AUTOSAR XML (schema 314)
package /ComponentType
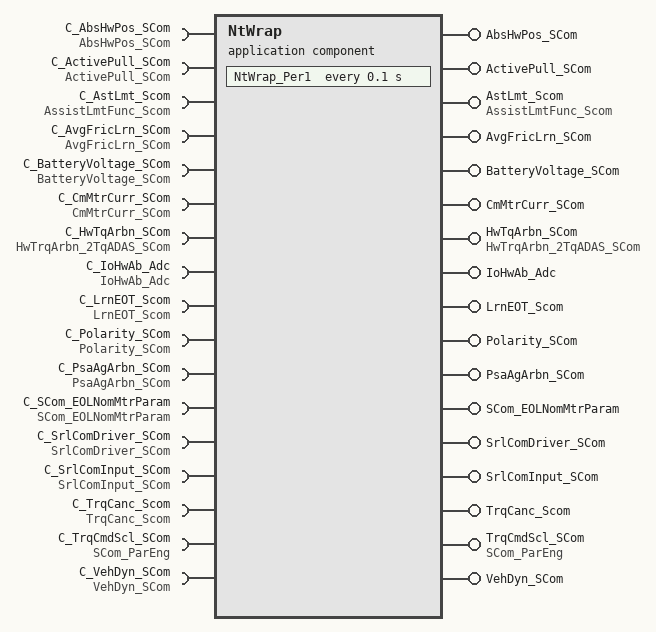
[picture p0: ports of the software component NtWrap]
  application software component type NtWrap
    17 x provide port:
      AbsHwPos_SCom: provided-interface=AbsHwPos_SCom
        provided-com-specs:
          operation=CustClrTrim, queue-length=1
          operation=CustSetTrim, queue-length=1
          operation=NxtClearTrim, queue-length=1
          operation=NxtSetTrim, queue-length=1
      ActivePull_SCom: provided-interface=ActivePull_SCom
        provided-com-specs:
          operation=ReadParam, queue-length=1
          operation=Reset, queue-length=1
          operation=SetLTComp, queue-length=1
          operation=SetSTComp, queue-length=1
      AstLmt_Scom: server-com-spec{operation=ManualTrqCmd, queue-length=1}, provided-interface=AssistLmtFunc_Scom
      AvgFricLrn_SCom: provided-interface=AvgFricLrn_SCom
        provided-com-specs:
          operation=CaptureOnTheFly, queue-length=1
          operation=GetEOLFric, queue-length=1
          operation=GetOffsetOutputDefeat, queue-length=1
          operation=GetSelect, queue-length=1
          operation=InitLearnedTables, queue-length=1
          operation=ResetToZero, queue-length=1
          operation=SetEOLFric, queue-length=1
          operation=SetOffsetOutputDefeat, queue-length=1
          operation=SetSelect, queue-length=1
      BatteryVoltage_SCom: provided-com-specs=[{operation=ClearTransOvData, queue-length=1}, {operation=ReadTransOvData, queue-length=1}], provided-interface=BatteryVoltage_SCom
      CmMtrCurr_SCom: provided-interface=CmMtrCurr_SCom
        provided-com-specs:
          operation=CalGain, queue-length=1
          operation=CalOffset, queue-length=1
          operation=MtrCurrOffReadStatus, queue-length=1
          operation=ReadMtrCurrCals, queue-length=1
          operation=SetMtrCurrCals, queue-length=1
      HwTqArbn_SCom: provided-interface=HwTrqArbn_2TqADAS_SCom
        provided-com-specs:
          operation=ClrHwTrqArbOffsetTrim, queue-length=1
          operation=ReadHwTrqArbOffsetTrim, queue-length=1
          operation=SetHwTrqArbOffsetTrim, queue-length=1
          operation=WriteHwTrqArbOffsetTrim, queue-length=1
      IoHwAb_Adc: server-com-spec{operation=ResetAdcEnable, queue-length=1}, provided-interface=IoHwAb_Adc
      LrnEOT_Scom: server-com-spec{operation=ResetEOT, queue-length=1}, provided-interface=LrnEOT_Scom
      Polarity_SCom: provided-com-specs=[{operation=ReadPolarity, queue-length=1}, {operation=SetPolarity, queue-length=1}], provided-interface=Polarity_SCom
      PsaAgArbn_SCom: server-com-spec{operation=PsaAaCmd, queue-length=1}, provided-interface=PsaAgArbn_SCom
      SCom_EOLNomMtrParam: provided-com-specs=[{operation=Get, queue-length=1}, {operation=Set, queue-length=1}], provided-interface=SCom_EOLNomMtrParam
      SrlComDriver_SCom: provided-interface=SrlComDriver_SCom
        provided-com-specs:
          operation=ElecIntStart, queue-length=1
          operation=ElecIntStop, queue-length=1
          operation=GetBusOffCounter, queue-length=1
          operation=SendMsgOnChange, queue-length=1
      SrlComInput_SCom: provided-interface=SrlComInput_SCom
        provided-com-specs:
          operation=GetNetworkDiagFltAcc, queue-length=1
          operation=ManualVehSpd, queue-length=1
          operation=ResetTimers, queue-length=1
          operation=VehSpdControl, queue-length=1
      TrqCanc_Scom: provided-interface=TrqCanc_Scom
        provided-com-specs:
          operation=ReadCogTrqCal, queue-length=1
          operation=ReadCogTrqCalComp, queue-length=1
          operation=SetCogTrqCal, queue-length=1
          operation=SetCogTrqCalComp, queue-length=1
      TrqCmdScl_SCom: provided-com-specs=[{operation=Get, queue-length=1}, {operation=Set, queue-length=1}], provided-interface=SCom_ParEng
      VehDyn_SCom: provided-com-specs=[{operation=ForceCenter, queue-length=1}, {operation=ResetCenter, queue-length=1}], provided-interface=VehDyn_SCom
    17 x require port:
      C_AbsHwPos_SCom: required-com-specs=[CustClrTrim, CustSetTrim, NxtClearTrim, NxtSetTrim], required-interface=AbsHwPos_SCom
      C_ActivePull_SCom: required-com-specs=[ReadParam, Reset, SetLTComp, SetSTComp], required-interface=ActivePull_SCom
      C_AstLmt_Scom: client-com-spec=ManualTrqCmd, required-interface=AssistLmtFunc_Scom
      C_AvgFricLrn_SCom: required-interface=AvgFricLrn_SCom
        required-com-specs:
          CaptureOnTheFly
          GetEOLFric
          GetOffsetOutputDefeat
          GetSelect
          InitLearnedTables
          ResetToZero
          SetEOLFric
          SetOffsetOutputDefeat
          SetSelect
      C_BatteryVoltage_SCom: required-com-specs=[ClearTransOvData, ReadTransOvData], required-interface=BatteryVoltage_SCom
      C_CmMtrCurr_SCom: required-com-specs=[CalGain, CalOffset, MtrCurrOffReadStatus, ReadMtrCurrCals, SetMtrCurrCals], required-interface=CmMtrCurr_SCom
      C_HwTqArbn_SCom: required-com-specs=[ClrHwTrqArbOffsetTrim, ReadHwTrqArbOffsetTrim, SetHwTrqArbOffsetTrim, WriteHwTrqArbOffsetTrim], required-interface=HwTrqArbn_2TqADAS_SCom
      C_IoHwAb_Adc: client-com-spec=ResetAdcEnable, required-interface=IoHwAb_Adc
      C_LrnEOT_Scom: client-com-spec=ResetEOT, required-interface=LrnEOT_Scom
      C_Polarity_SCom: required-com-specs=[ReadPolarity, SetPolarity], required-interface=Polarity_SCom
      C_PsaAgArbn_SCom: client-com-spec=PsaAaCmd, required-interface=PsaAgArbn_SCom
      C_SCom_EOLNomMtrParam: required-com-specs=[Get, Set], required-interface=SCom_EOLNomMtrParam
      C_SrlComDriver_SCom: required-com-specs=[ElecIntStart, ElecIntStop, GetBusOffCounter, SendMsgOnChange], required-interface=SrlComDriver_SCom
      C_SrlComInput_SCom: required-com-specs=[GetNetworkDiagFltAcc, ManualVehSpd, ResetTimers, VehSpdControl], required-interface=SrlComInput_SCom
      C_TrqCanc_Scom: required-com-specs=[ReadCogTrqCal, ReadCogTrqCalComp, SetCogTrqCal, SetCogTrqCalComp], required-interface=TrqCanc_Scom
      C_TrqCmdScl_SCom: required-com-specs=[Get, Set], required-interface=SCom_ParEng
      C_VehDyn_SCom: required-com-specs=[ForceCenter, ResetCenter], required-interface=VehDyn_SCom
  internal behavior NtWrap_InternalBehavior: component=NtWrap
    timing event TMT_NtWrap_Per1: start-on-event=NtWrap_Per1, period=0.1
    33 x operation invoked event:
      OIT_NtWrapC_AbsHwPos_SCom_CustClrTrim_AbsHwPos_SCom_CustClrTrim: start-on-event=NtWrapC_AbsHwPos_SCom_CustClrTrim, operation=AbsHwPos_SCom.CustClrTrim
      OIT_NtWrapC_AbsHwPos_SCom_CustSetTrim_AbsHwPos_SCom_CustSetTrim: start-on-event=NtWrapC_AbsHwPos_SCom_CustSetTrim, operation=AbsHwPos_SCom.CustSetTrim
      OIT_NtWrapC_AbsHwPos_SCom_NxtClearTrim_AbsHwPos_SCom_NxtClearTrim: start-on-event=NtWrapC_AbsHwPos_SCom_NxtClearTrim, operation=AbsHwPos_SCom.NxtClearTrim
      OIT_NtWrapC_AbsHwPos_SCom_NxtSetTrim_AbsHwPos_SCom_NxtSetTrim: start-on-event=NtWrapC_AbsHwPos_SCom_NxtSetTrim, operation=AbsHwPos_SCom.NxtSetTrim
      OIT_NtWrapC_ActivePull_SCom_SetLTComp_ActivePull_SCom_SetLTComp: start-on-event=NtWrapC_ActivePull_SCom_SetLTComp, operation=ActivePull_SCom.SetLTComp
      OIT_NtWrapC_ActivePull_SCom_SetSTComp_ActivePull_SCom_SetSTComp: start-on-event=NtWrapC_ActivePull_SCom_SetSTComp, operation=ActivePull_SCom.SetSTComp
      OIT_NtWrapC_AstLmt_Scom_ManualTrqCmd_AstLmt_Scom_ManualTrqCmd: start-on-event=NtWrapC_AstLmt_Scom_ManualTrqCmd, operation=AstLmt_Scom.ManualTrqCmd
      OIT_NtWrapC_AvgFricLrn_SCom_InitLearnedTables_AvgFricLrn_SCom_InitLearnedTables: start-on-event=NtWrapC_AvgFricLrn_SCom_InitLearnedTables, operation=AvgFricLrn_SCom.InitLearnedTables
      OIT_NtWrapC_AvgFricLrn_SCom_ResetToZero_AvgFricLrn_SCom_ResetToZero: start-on-event=NtWrapC_AvgFricLrn_SCom_ResetToZero, operation=AvgFricLrn_SCom.ResetToZero
      OIT_NtWrapC_AvgFricLrn_SCom_SetEOLFric_AvgFricLrn_SCom_SetEOLFric: start-on-event=NtWrapC_AvgFricLrn_SCom_SetEOLFric, operation=AvgFricLrn_SCom.SetEOLFric
      OIT_NtWrapC_AvgFricLrn_SCom_SetOffsetOutputDefeat_AvgFricLrn_SCom_SetOffsetOutputDefeat: start-on-event=NtWrapC_AvgFricLrn_SCom_SetOffsetOutputDefeat, operation=AvgFricLrn_SCom.SetOffsetOutputDefeat
      OIT_NtWrapC_AvgFricLrn_SCom_SetSelect_AvgFricLrn_SCom_SetSelect: start-on-event=NtWrapC_AvgFricLrn_SCom_SetSelect, operation=AvgFricLrn_SCom.SetSelect
      OIT_NtWrapC_BatteryVoltage_SCom_ClearTransOvData_BatteryVoltage_SCom_ClearTransOvData: start-on-event=NtWrapC_BatteryVoltage_SCom_ClearTransOvData, operation=BatteryVoltage_SCom.ClearTransOvData
      OIT_NtWrapC_CmMtrCurr_SCom_CalGain_CmMtrCurr_SCom_CalGain: start-on-event=NtWrapC_CmMtrCurr_SCom_CalGain, operation=CmMtrCurr_SCom.CalGain
      OIT_NtWrapC_CmMtrCurr_SCom_CalOffset_CmMtrCurr_SCom_CalOffset: start-on-event=NtWrapC_CmMtrCurr_SCom_CalOffset, operation=CmMtrCurr_SCom.CalOffset
      OIT_NtWrapC_CmMtrCurr_SCom_SetMtrCurrCals_CmMtrCurr_SCom_SetMtrCurrCals: start-on-event=NtWrapC_CmMtrCurr_SCom_SetMtrCurrCals, operation=CmMtrCurr_SCom.SetMtrCurrCals
      OIT_NtWrapC_HwTqArbn_SCom_ClrTrqTrim_HwTqArbn_SCom_ClrHwTrqArbOffsetTrim: start-on-event=NtWrapC_HwTqArbn_SCom_ClrTrqTrim, operation=HwTqArbn_SCom.ClrHwTrqArbOffsetTrim
      OIT_NtWrapC_HwTqArbn_SCom_SetTrqTrim_HwTqArbn_SCom_SetHwTrqArbOffsetTrim: start-on-event=NtWrapC_HwTqArbn_SCom_SetTrqTrim, operation=HwTqArbn_SCom.SetHwTrqArbOffsetTrim
      OIT_NtWrapC_HwTqArbn_SCom_WriteData_HwTqArbn_SCom_WriteHwTrqArbOffsetTrim: start-on-event=NtWrapC_HwTqArbn_SCom_WriteData, operation=HwTqArbn_SCom.WriteHwTrqArbOffsetTrim
      OIT_NtWrapC_IoHwAb_Adc_ResetAdcEnable_IoHwAb_Adc_ResetAdcEnable: start-on-event=NtWrapC_IoHwAb_Adc_ResetAdcEnable, operation=IoHwAb_Adc.ResetAdcEnable
      OIT_NtWrapC_LrnEOT_Scom_ResetEOT_LrnEOT_Scom_ResetEOT: start-on-event=NtWrapC_LrnEOT_Scom_ResetEOT, operation=LrnEOT_Scom.ResetEOT
      OIT_NtWrapC_Polarity_SCom_SetPolarity_Polarity_SCom_SetPolarity: start-on-event=NtWrapC_Polarity_SCom_SetPolarity, operation=Polarity_SCom.SetPolarity
      OIT_NtWrapC_PsaAgArbn_SCom_PsaAaCmd_PsaAgArbn_SCom_PsaAaCmd: start-on-event=NtWrapC_PsaAgArbn_SCom_PsaAaCmd, operation=PsaAgArbn_SCom.PsaAaCmd
      OIT_NtWrapC_SCom_EOLNomMtrParam_Set_SCom_EOLNomMtrParam_Set: start-on-event=NtWrapC_SCom_EOLNomMtrParam_Set, operation=SCom_EOLNomMtrParam.Set
      OIT_NtWrapC_SrlComDriver_SCom_ElecIntStart_SrlComDriver_SCom_ElecIntStart: start-on-event=NtWrapC_SrlComDriver_SCom_ElecIntStart, operation=SrlComDriver_SCom.ElecIntStart
      OIT_NtWrapC_SrlComDriver_SCom_ElecIntStop_SrlComDriver_SCom_ElecIntStop: start-on-event=NtWrapC_SrlComDriver_SCom_ElecIntStop, operation=SrlComDriver_SCom.ElecIntStop
      OIT_NtWrapC_SrlComDriver_SCom_SendMsgOnChange_SrlComDriver_SCom_SendMsgOnChange: start-on-event=NtWrapC_SrlComDriver_SCom_SendMsgOnChange, operation=SrlComDriver_SCom.SendMsgOnChange
      OIT_NtWrapC_SrlComInput_SCom_ManualVehSpd_SrlComInput_SCom_ManualVehSpd: start-on-event=NtWrapC_SrlComInput_SCom_ManualVehSpd, operation=SrlComInput_SCom.ManualVehSpd
      OIT_NtWrapC_SrlComInput_SCom_ResetTimers_SrlComInput_SCom_ResetTimers: start-on-event=NtWrapC_SrlComInput_SCom_ResetTimers, operation=SrlComInput_SCom.ResetTimers
      OIT_NtWrapC_SrlComInput_SCom_VehSpdControl_SrlComInput_SCom_VehSpdControl: start-on-event=NtWrapC_SrlComInput_SCom_VehSpdControl, operation=SrlComInput_SCom.VehSpdControl
      OIT_NtWrapC_TrqCanc_Scom_SetCogTrqCal_TrqCanc_Scom_SetCogTrqCal: start-on-event=NtWrapC_TrqCanc_Scom_SetCogTrqCal, operation=TrqCanc_Scom.SetCogTrqCal
      OIT_NtWrapC_TrqCmdScl_SCom_Set_TrqCmdScl_SCom_Set: start-on-event=NtWrapC_TrqCmdScl_SCom_Set, operation=TrqCmdScl_SCom.Set
      OIT_NtWrapC_VehDyn_SCom_ResetCenter_VehDyn_SCom_ResetCenter: start-on-event=NtWrapC_VehDyn_SCom_ResetCenter, operation=VehDyn_SCom.ResetCenter
    port-api-options:
      enable-take-address=false, indirect-api=false, port=AbsHwPos_SCom
      enable-take-address=false, indirect-api=false, port=ActivePull_SCom
      enable-take-address=false, indirect-api=false, port=AstLmt_Scom
      enable-take-address=false, indirect-api=false, port=AvgFricLrn_SCom
      enable-take-address=false, indirect-api=false, port=BatteryVoltage_SCom
      enable-take-address=false, indirect-api=false, port=C_AbsHwPos_SCom
      enable-take-address=false, indirect-api=false, port=C_ActivePull_SCom
      enable-take-address=false, indirect-api=false, port=C_AstLmt_Scom
      enable-take-address=false, indirect-api=false, port=C_AvgFricLrn_SCom
      enable-take-address=false, indirect-api=false, port=C_BatteryVoltage_SCom
      enable-take-address=false, indirect-api=false, port=C_CmMtrCurr_SCom
      enable-take-address=false, indirect-api=false, port=C_HwTqArbn_SCom
      enable-take-address=false, indirect-api=false, port=C_IoHwAb_Adc
      enable-take-address=false, indirect-api=false, port=C_LrnEOT_Scom
      enable-take-address=false, indirect-api=false, port=C_Polarity_SCom
      enable-take-address=false, indirect-api=false, port=C_PsaAgArbn_SCom
      enable-take-address=false, indirect-api=false, port=C_SCom_EOLNomMtrParam
      enable-take-address=false, indirect-api=false, port=C_SrlComDriver_SCom
      enable-take-address=false, indirect-api=false, port=C_SrlComInput_SCom
      enable-take-address=false, indirect-api=false, port=C_TrqCanc_Scom
      enable-take-address=false, indirect-api=false, port=C_TrqCmdScl_SCom
      enable-take-address=false, indirect-api=false, port=C_VehDyn_SCom
      enable-take-address=false, indirect-api=false, port=CmMtrCurr_SCom
      enable-take-address=false, indirect-api=false, port=HwTqArbn_SCom
      enable-take-address=false, indirect-api=false, port=IoHwAb_Adc
      enable-take-address=false, indirect-api=false, port=LrnEOT_Scom
      enable-take-address=false, indirect-api=false, port=Polarity_SCom
      enable-take-address=false, indirect-api=false, port=PsaAgArbn_SCom
      enable-take-address=false, indirect-api=false, port=SCom_EOLNomMtrParam
      enable-take-address=false, indirect-api=false, port=SrlComDriver_SCom
      enable-take-address=false, indirect-api=false, port=SrlComInput_SCom
      enable-take-address=false, indirect-api=false, port=TrqCanc_Scom
      enable-take-address=false, indirect-api=false, port=TrqCmdScl_SCom
      enable-take-address=false, indirect-api=false, port=VehDyn_SCom
    34 x runnable:
      NtWrap_Per1
        sync call SC_C_SrlComDriver_SCom_GetBusOffCounter: operation=C_SrlComDriver_SCom.GetBusOffCounter, timeout=0
      NtWrapC_AbsHwPos_SCom_CustClrTrim
        sync call SC_C_AbsHwPos_SCom_CustClrTrim: operation=C_AbsHwPos_SCom.CustClrTrim, timeout=0
      NtWrapC_AbsHwPos_SCom_CustSetTrim
        sync call SC_C_AbsHwPos_SCom_CustSetTrim: operation=C_AbsHwPos_SCom.CustSetTrim, timeout=0
      NtWrapC_AbsHwPos_SCom_NxtClearTrim
        sync call SC_C_AbsHwPos_SCom_NxtClearTrim: operation=C_AbsHwPos_SCom.NxtClearTrim, timeout=0
      NtWrapC_AbsHwPos_SCom_NxtSetTrim
        sync call SC_C_AbsHwPos_SCom_NxtSetTrim: operation=C_AbsHwPos_SCom.NxtSetTrim, timeout=0
      NtWrapC_ActivePull_SCom_SetLTComp
        sync call SC_C_ActivePull_SCom_SetLTComp: operation=C_ActivePull_SCom.SetLTComp, timeout=0
      NtWrapC_ActivePull_SCom_SetSTComp
        sync call SC_C_ActivePull_SCom_SetSTComp: operation=C_ActivePull_SCom.SetSTComp, timeout=0
      NtWrapC_AstLmt_Scom_ManualTrqCmd
        sync call SC_C_AstLmt_Scom_ManualTrqCmd: operation=C_AstLmt_Scom.ManualTrqCmd, timeout=0
      NtWrapC_AvgFricLrn_SCom_InitLearnedTables
        sync call SC_C_AvgFricLrn_SCom_InitLearnedTables: operation=C_AvgFricLrn_SCom.InitLearnedTables, timeout=0
      NtWrapC_AvgFricLrn_SCom_ResetToZero
        sync call SC_C_AvgFricLrn_SCom_ResetToZero: operation=C_AvgFricLrn_SCom.ResetToZero, timeout=0
      NtWrapC_AvgFricLrn_SCom_SetEOLFric
        sync call SC_C_AvgFricLrn_SCom_SetEOLFric: operation=C_AvgFricLrn_SCom.SetEOLFric, timeout=0
      NtWrapC_AvgFricLrn_SCom_SetOffsetOutputDefeat
        sync call SC_C_AvgFricLrn_SCom_SetOffsetOutputDefeat: operation=C_AvgFricLrn_SCom.SetOffsetOutputDefeat, timeout=0
      NtWrapC_AvgFricLrn_SCom_SetSelect
        sync call SC_C_AvgFricLrn_SCom_SetSelect: operation=C_AvgFricLrn_SCom.SetSelect, timeout=0
      NtWrapC_BatteryVoltage_SCom_ClearTransOvData
        sync call SC_C_BatteryVoltage_SCom_ClearTransOvData: operation=C_BatteryVoltage_SCom.ClearTransOvData, timeout=0
      NtWrapC_CmMtrCurr_SCom_CalGain
        sync call SC_C_CmMtrCurr_SCom_CalGain: operation=C_CmMtrCurr_SCom.CalGain, timeout=0
      NtWrapC_CmMtrCurr_SCom_CalOffset
        sync call SC_C_CmMtrCurr_SCom_CalOffset: operation=C_CmMtrCurr_SCom.CalOffset, timeout=0
      NtWrapC_CmMtrCurr_SCom_SetMtrCurrCals
        sync call SC_C_CmMtrCurr_SCom_SetMtrCurrCals: operation=C_CmMtrCurr_SCom.SetMtrCurrCals, timeout=0
      NtWrapC_HwTqArbn_SCom_ClrTrqTrim
        sync call SC_C_HwTqArbn_SCom_ClrHwTrqArbOffsetTrim: operation=C_HwTqArbn_SCom.ClrHwTrqArbOffsetTrim, timeout=0
      NtWrapC_HwTqArbn_SCom_SetTrqTrim
        sync call SC_C_HwTqArbn_SCom_SetHwTrqArbOffsetTrim: operation=C_HwTqArbn_SCom.SetHwTrqArbOffsetTrim, timeout=0
      NtWrapC_HwTqArbn_SCom_WriteData
        sync call SC_C_HwTqArbn_SCom_WriteHwTrqArbOffsetTrim: operation=C_HwTqArbn_SCom.WriteHwTrqArbOffsetTrim, timeout=0
      NtWrapC_IoHwAb_Adc_ResetAdcEnable
        sync call SC_C_IoHwAb_Adc_ResetAdcEnable: operation=C_IoHwAb_Adc.ResetAdcEnable, timeout=0
      NtWrapC_LrnEOT_Scom_ResetEOT
        sync call SC_C_LrnEOT_Scom_ResetEOT: operation=C_LrnEOT_Scom.ResetEOT, timeout=0
      NtWrapC_Polarity_SCom_SetPolarity
        sync call SC_C_Polarity_SCom_SetPolarity: operation=C_Polarity_SCom.SetPolarity, timeout=0
      NtWrapC_PsaAgArbn_SCom_PsaAaCmd
        sync call SC_C_PsaAgArbn_SCom_PsaAaCmd: operation=C_PsaAgArbn_SCom.PsaAaCmd, timeout=0
      NtWrapC_SCom_EOLNomMtrParam_Set
        sync call SC_C_SCom_EOLNomMtrParam_Set: operation=C_SCom_EOLNomMtrParam.Set, timeout=0
      NtWrapC_SrlComDriver_SCom_ElecIntStart
        sync call SC_C_SrlComDriver_SCom_ElecIntStart: operation=C_SrlComDriver_SCom.ElecIntStart, timeout=0
      NtWrapC_SrlComDriver_SCom_ElecIntStop
        sync call SC_C_SrlComDriver_SCom_ElecIntStop: operation=C_SrlComDriver_SCom.ElecIntStop, timeout=0
      NtWrapC_SrlComDriver_SCom_SendMsgOnChange
        sync call SC_C_SrlComDriver_SCom_SendMsgOnChange: operation=C_SrlComDriver_SCom.SendMsgOnChange, timeout=0
      NtWrapC_SrlComInput_SCom_ManualVehSpd
        sync call SC_C_SrlComInput_SCom_ManualVehSpd: operation=C_SrlComInput_SCom.ManualVehSpd, timeout=0
      NtWrapC_SrlComInput_SCom_ResetTimers
        sync call SC_C_SrlComInput_SCom_ResetTimers: operation=C_SrlComInput_SCom.ResetTimers, timeout=0
      NtWrapC_SrlComInput_SCom_VehSpdControl
        sync call SC_C_SrlComInput_SCom_VehSpdControl: operation=C_SrlComInput_SCom.VehSpdControl, timeout=0
      NtWrapC_TrqCanc_Scom_SetCogTrqCal
        sync call SC_C_TrqCanc_Scom_SetCogTrqCal: operation=C_TrqCanc_Scom.SetCogTrqCal, timeout=0
      NtWrapC_TrqCmdScl_SCom_Set
        sync call SC_C_TrqCmdScl_SCom_Set: operation=C_TrqCmdScl_SCom.Set, timeout=0
      NtWrapC_VehDyn_SCom_ResetCenter
        sync call SC_C_VehDyn_SCom_ResetCenter: operation=C_VehDyn_SCom.ResetCenter, timeout=0
  swc implementation NtWrap_Implementation: behavior=NtWrap_InternalBehavior
    code-descriptors:
      code Code: type=SRC
